# APM32F427 register map
File version: 1.0
CPU: CM4 r1p0, little endian, no MPU, no FPU, 4 interrupt priority bits
Registers are 32-bit, read-write, reset 0x0 unless marked. A register's access mark holds for its fields unless they carry their own. Offsets are from the block's base; [hi:lo] are bit positions; {n}, {i} and the like mark numbered series.

## DMC — Dynamic memory controler
Base 0xA0000000; alternate view of SMC
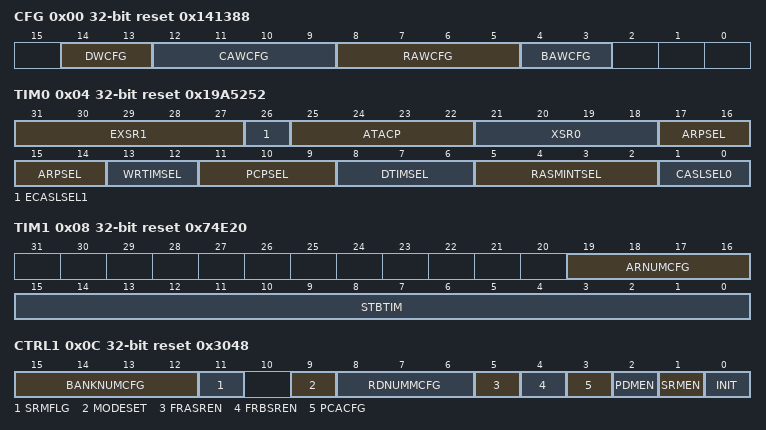
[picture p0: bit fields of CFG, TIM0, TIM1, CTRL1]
0x00 CFG reset 0x141388 — Configuraion register
  [14:13] DWCFG — Data Width Configure
  [12:9] CAWCFG — Column Address Width Configure
  [8:5] RAWCFG — Row Address Width Configure
  [4:3] BAWCFG — Bank Address Width Configure
0x04 TIM0 reset 0x19A5252 — Timing register 0
  [31:27] EXSR1
  [26] ECASLSEL1 — Extended CAS Latency
  [25:22] ATACP — Active to active
  [21:18] XSR0
  [17:14] ARPSEL — Auto-Refresh Period Select
  [13:12] WRTIMSEL
  [11:9] PCPSEL — Precharge Period Select
  [8:6] DTIMSEL — RAS To CAS Delay Time Select
  [5:2] RASMINTSEL — RAS Minimum Time Select
  [1:0] CASLSEL0 — CAS Latency Select
0x08 TIM1 reset 0x74E20 — Timing register 1
  [19:16] ARNUMCFG — Number Of Auto-Refresh During Initialization Configure
  [15:0] STBTIM — Stable Time
0x0C CTRL1 access per field reset 0x3048 — Control register 1
  [15:12] BANKNUMCFG rw — Number Of Open Banks Configure
  [11] SRMFLG ro — Self-refresh mode flag
  [9] MODESET rw — Mode Setup
  [8:6] RDNUMMCFG rw — Configure Number Of Registers Inserted In Read Data Path
  [5] FRASREN rw — Full Refresh After Exit Self-Refresh Mode
  [4] FRBSREN rw — Full Refresh Before Entering Self-Refresh Mode
  [3] PCACFG rw — Precharge Algorithm Configure
  [2] PDMEN rw — Put SDRM in Power-Down Mode Enable
  [1] SRMEN rw — Put SDRM in Self-Refresh Mode Enable
  [0] INIT rw — SDRAM Initialize
0x10 REF reset 0xC3 — refresh register
  [15:0] RCYCCFG
0x400 SW — switch register
  [0] MCSW — Memory Controller Function Switch
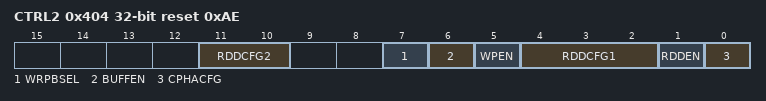
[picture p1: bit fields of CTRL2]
0x404 CTRL2 reset 0xAE — Control register 2
  [11:10] RDDCFG2 — RD Clock Delay Configure
  [7] WRPBSEL — WRAP Burst Type Selection
  [6] BUFFEN — DMC Accelerate Module Enable
  [5] WPEN — Write Pipe Enable
  [4:2] RDDCFG1 — RD Clock Delay Configure
  [1] RDDEN — RD Delay Function Enable
  [0] CPHACFG — Clock Phase Configure

## RNG — Random number generator
Base 0x50060800
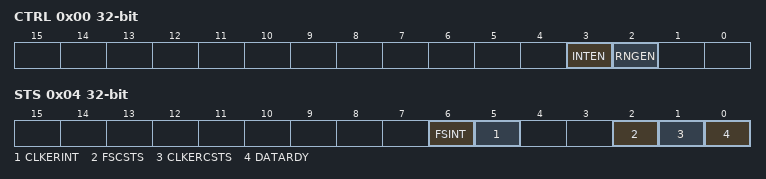
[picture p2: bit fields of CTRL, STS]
0x00 CTRL — control register
  [3] INTEN — Interrupt enable
  [2] RNGEN — Random number generator enable
0x04 STS access per field — status register
  [6] FSINT rw — Seed error interrupt status
  [5] CLKERINT rw — Clock error interrupt status
  [2] FSCSTS ro — Seed error current status
  [1] CLKERCSTS ro — Clock error current status
  [0] DATARDY ro — Data ready
0x08 DATA ro
  [31:0] DATA — Random data

## CRC — Cryptographic processor
Base 0x40023000
0x00 DATA reset 0xFFFFFFFF
0x04 INDATA — Independent Data register
  [7:0] INDATA
0x08 CTRL wo — Control register
  [0] RST — Reset CRC Calculation Unit

## GPIOC — General-purpose I/Os
Base 0x40020800
Same registers: GPIOD 0x40020C00, GPIOE 0x40021000, GPIOF 0x40021400, GPIOG 0x40021800, GPIOH 0x40021C00
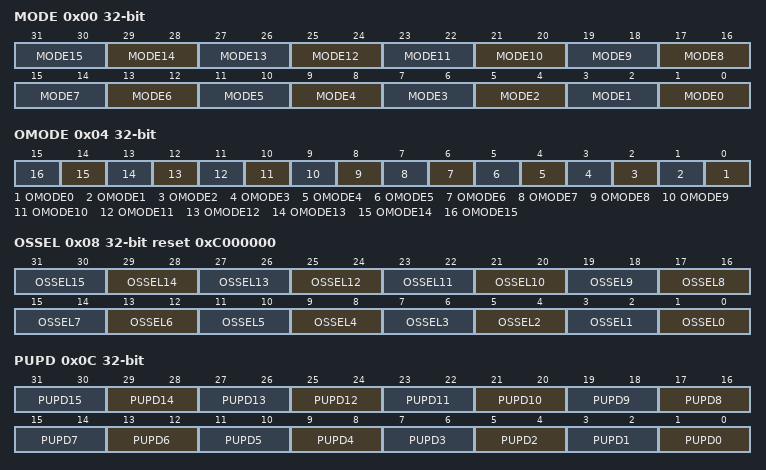
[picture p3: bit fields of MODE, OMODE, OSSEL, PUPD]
0x00 MODE — GPIO port mode register
  [2n+1:2n] MODE{n} (n=0..15) — Port x configuration bits (y = 0..15)
0x04 OMODE — GPIO port output type register
  [n] OMODE{n} (n=0..15) — Port x configuration bits (y = 0..15)
0x08 OSSEL reset 0xC000000 — GPIO port output speed register
  [2n+1:2n] OSSEL{n} (n=0..15) — Port x configuration bits (y = 0..15)
0x0C PUPD — GPIO port pull-up/pull-down register
  [2n+1:2n] PUPD{n} (n=0..15) — Port x configuration bits (y = 0..15)
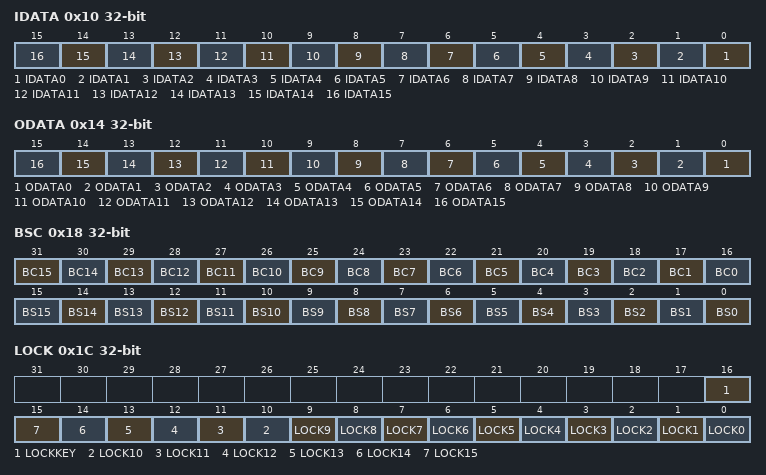
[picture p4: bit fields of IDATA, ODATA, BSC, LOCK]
0x10 IDATA ro — GPIO port input data register
  [n] IDATA{n} (n=0..15) — Port input data (y = 0..15)
0x14 ODATA — GPIO port output data register
  [n] ODATA{n} (n=0..15) — Port output data (y = 0..15)
0x18 BSC wo — GPIO port bit set/reset register
  [n+16] BC{n} (n=1..15) — Port x reset bit y (y = 0..15)
  [16] BC0 — Port x set bit y (y= 0..15)
  [n] BS{n} (n=0..15) — Port x set bit y (y= 0..15)
0x1C LOCK — GPIO port configuration lock register
  [16] LOCKKEY — Port x lock bit y (y= 0..15)
  [n] LOCK{n} (n=0..15) — Port x lock bit y (y= 0..15)
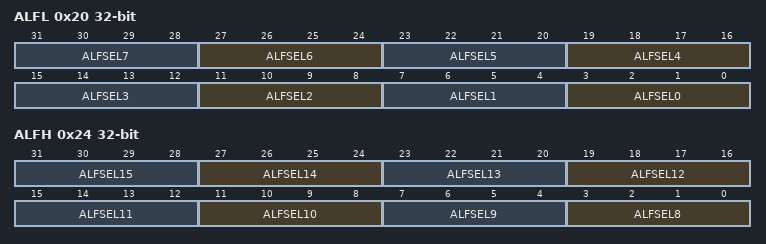
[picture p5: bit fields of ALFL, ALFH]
0x20 ALFL — GPIO alternate function low register
  [4n+3:4n] ALFSEL{n} (n=0..7) — Alternate function selection for port x bit y (y = 0..7)
0x24 ALFH — GPIO alternate function high register
  [4n-29:4n-32] ALFSEL{n} (n=8..15) — Alternate function selection for port x bit y (y = 8..15)

## GPIOB — General-purpose I/Os
Base 0x40020400
Registers as GPIOC; these are added or differ:
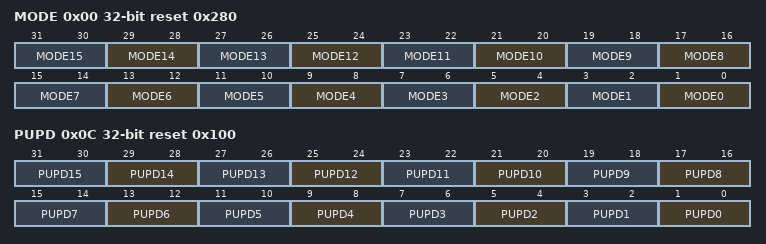
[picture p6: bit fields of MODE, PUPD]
0x00 MODE reset 0x280 — GPIO port mode register
  [2n+1:2n] MODE{n} (n=0..15) — Port x configuration bits (y = 0..15)
0x0C PUPD reset 0x100 — GPIO port pull-up/pull-down register
  [2n+1:2n] PUPD{n} (n=0..15) — Port x configuration bits (y = 0..15)

## GPIOA — General-purpose I/Os
Base 0x40020000
Registers as GPIOC; these are added or differ:
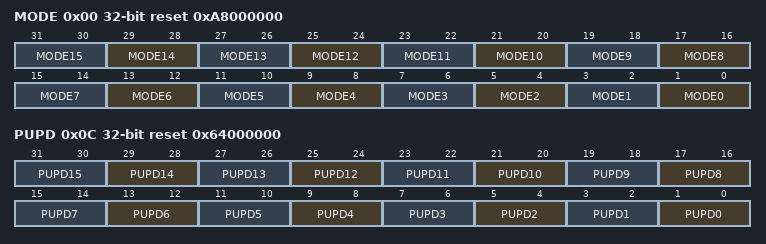
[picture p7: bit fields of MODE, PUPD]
0x00 MODE reset 0xA8000000 — GPIO port mode register
  [2n+1:2n] MODE{n} (n=0..15) — Port x configuration bits (y = 0..15)
0x0C PUPD reset 0x64000000 — GPIO port pull-up/pull-down register
  [2n+1:2n] PUPD{n} (n=0..15) — Port x configuration bits (y = 0..15)
